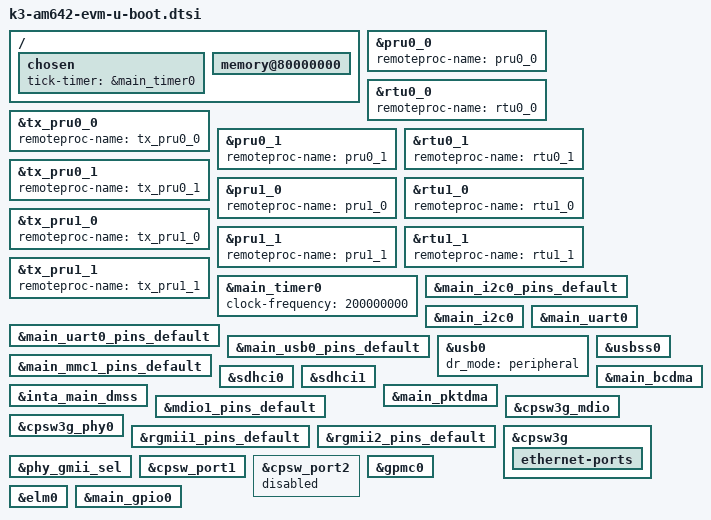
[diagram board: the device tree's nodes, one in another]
// SPDX-License-Identifier: GPL-2.0
/*
 * Copyright (C) 2020-2021 Texas Instruments Incorporated - https://www.ti.com/
 */

#include "k3-am64x-binman.dtsi"

/ {
	chosen {
		tick-timer = &main_timer0;
	};

	memory@80000000 {
		bootph-all;
	};
};

&pru0_0 {
	remoteproc-name = "pru0_0";
};

&rtu0_0 {
	remoteproc-name = "rtu0_0";
};

&tx_pru0_0 {
	remoteproc-name = "tx_pru0_0";
};

&pru0_1 {
	remoteproc-name = "pru0_1";
};

&rtu0_1 {
	remoteproc-name = "rtu0_1";
};

&tx_pru0_1 {
	remoteproc-name = "tx_pru0_1";
};

&pru1_0 {
	remoteproc-name = "pru1_0";
};

&rtu1_0 {
	remoteproc-name = "rtu1_0";
};

&tx_pru1_0 {
	remoteproc-name = "tx_pru1_0";
};

&pru1_1 {
	remoteproc-name = "pru1_1";
};

&rtu1_1 {
	remoteproc-name = "rtu1_1";
};

&tx_pru1_1 {
	remoteproc-name = "tx_pru1_1";
};

&main_timer0 {
	bootph-all;
	clock-frequency = <200000000>;
};

&main_i2c0_pins_default {
	bootph-all;
};

&main_i2c0 {
	bootph-all;
};

&main_uart0_pins_default {
	bootph-all;
};

&main_uart0 {
	bootph-all;
};

&main_usb0_pins_default {
	bootph-all;
};

&usb0 {
	dr_mode="peripheral";
	bootph-all;
};

&usbss0 {
	bootph-all;
};

&main_mmc1_pins_default {
	bootph-all;
};

&main_usb0_pins_default {
	bootph-all;
};

&sdhci0 {
	bootph-all;
};

&main_mmc1_pins_default {
	bootph-all;
};

&sdhci1 {
	bootph-all;
};

&inta_main_dmss {
	bootph-all;
};

&main_bcdma {
	bootph-all;
};

&main_pktdma {
	bootph-all;
};

&mdio1_pins_default {
	bootph-all;
};

&cpsw3g_mdio {
	bootph-all;
};

&cpsw3g_phy0 {
	bootph-all;
};

&rgmii1_pins_default {
	bootph-all;
};

&rgmii2_pins_default {
	bootph-all;
};

&cpsw3g {
	bootph-all;

	ethernet-ports {
		bootph-all;
	};
};

&phy_gmii_sel {
	bootph-all;
};

&cpsw_port1 {
	bootph-all;
};

&cpsw_port2 {
	status = "disabled";
};

&gpmc0 {
	bootph-all;
};

&elm0 {
	bootph-all;
};

&main_gpio0 {
	bootph-all;
};
